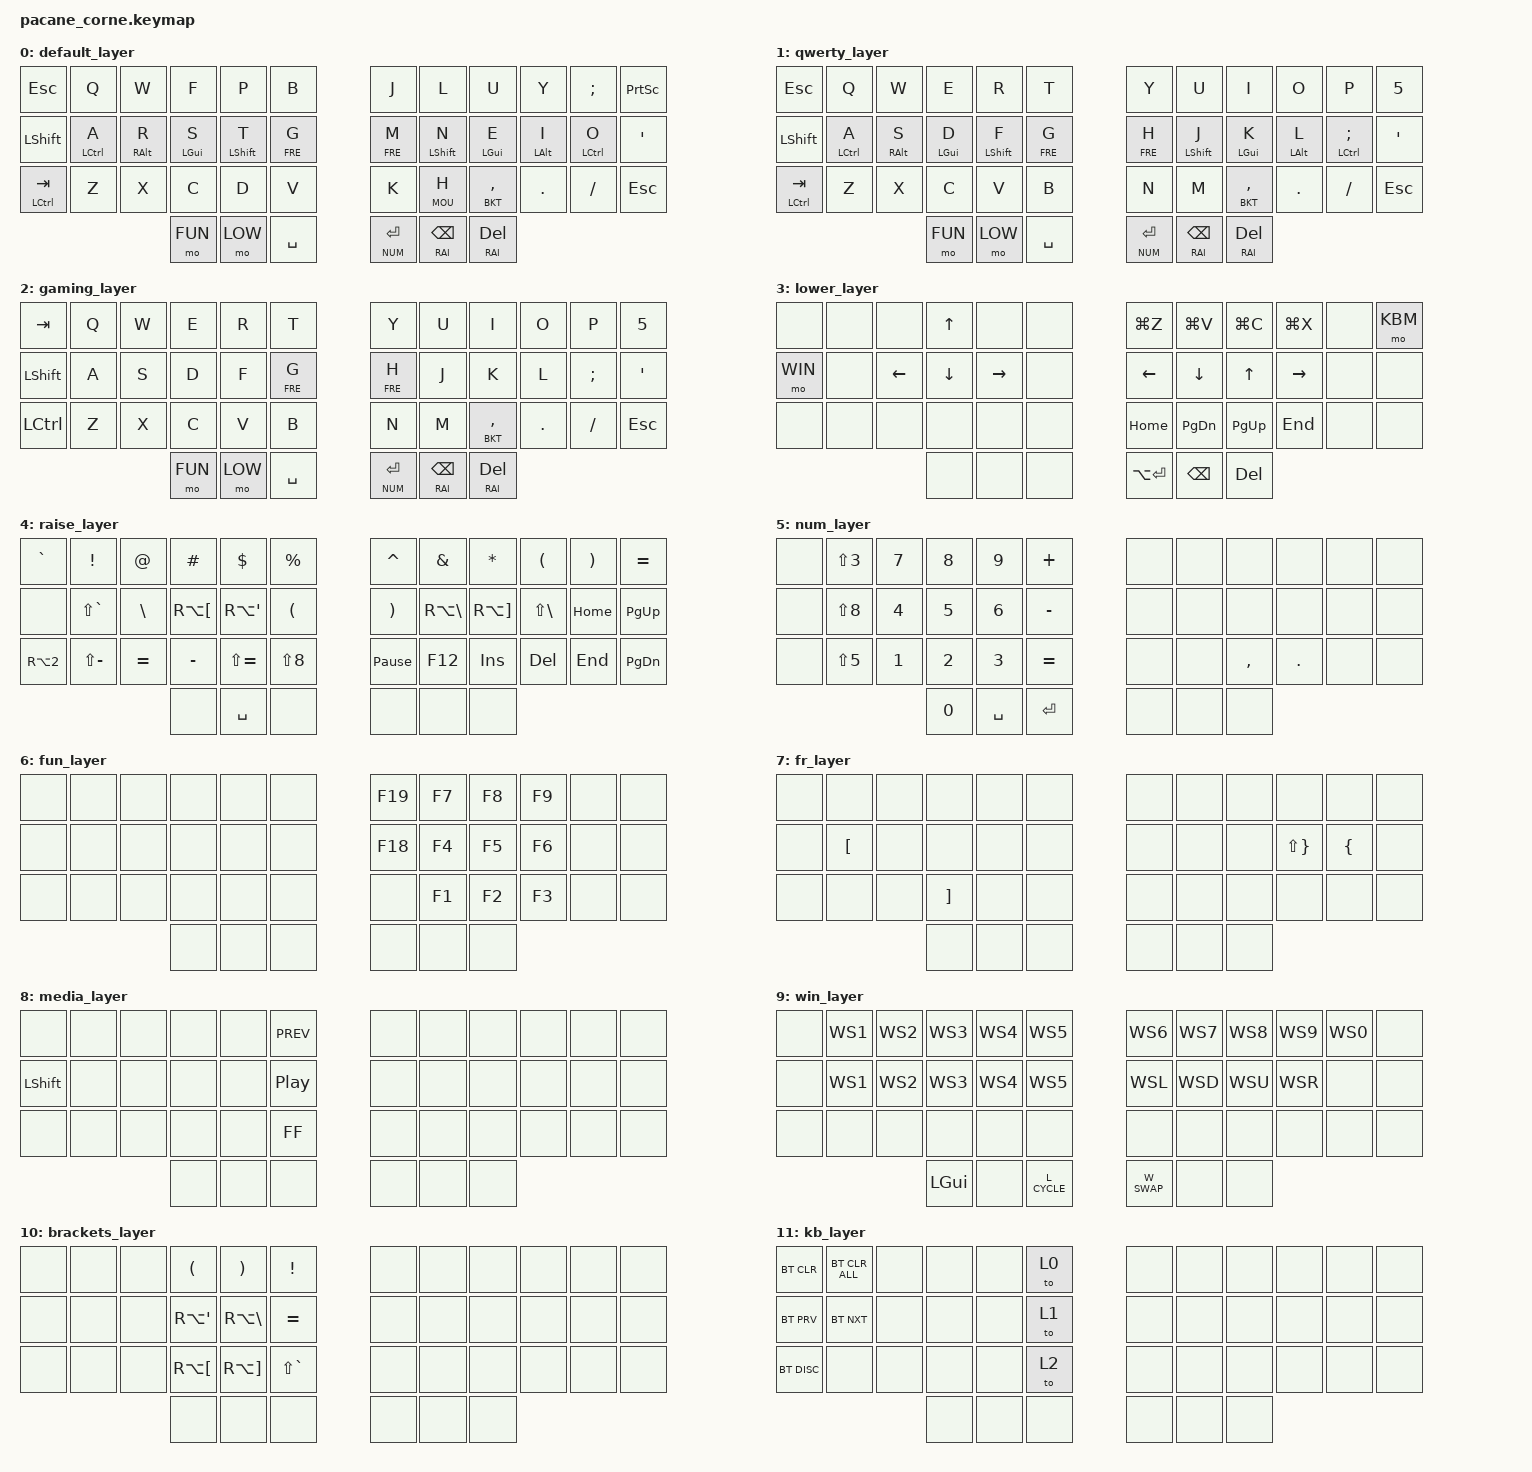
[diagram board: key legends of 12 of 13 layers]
#include <behaviors.dtsi>
#include <dt-bindings/zmk/keys.h>
#include <dt-bindings/zmk/bt.h>
#include "zmk-helpers/helper.h"

#define ZMK_POINTING_DEFAULT_MOVE_VAL 1500  // default: 600

#include <dt-bindings/zmk/mouse.h>
#include <dt-bindings/zmk/pointing.h>

#define L_SQ_BKT &kp RA(LBKT)
#define R_SQ_BKT &kp RA(RBKT)

#define L_CL_BKT &kp RA(SQT)
#define R_CL_BKT &kp RA(BSLH)

#define L_CHEV &kp BSLH
#define R_CHEV &kp LS(BSLH)

#define _PLUS &kp LS(EQUAL)
#define _PIPE &kp LS(GRAVE)
#define UNDSCR &kp LS(MINUS)
#define MULTPL &kp LS(N8)
#define _AT &kp RA(N2)
#define AMPRS &kp LS(N7)
#define TREMA &kp LS(RBRC)

#define WS1 LC(LS(LA(N1)))
#define WS2 LC(LS(LA(N2)))
#define WS3 LC(LS(LA(N3)))
#define WS4 LC(LS(LA(N4)))
#define WS5 LC(LS(LA(N5)))
#define WS6 LC(LS(LA(N6)))
#define WS7 LC(LS(LA(N7)))
#define WS8 LC(LS(LA(N8)))
#define WS9 LC(LS(LA(N9)))
#define WS0 LC(LS(LA(N0)))

#define WSL LC(LS(LA(H)))
#define WSD LC(LS(LA(J)))
#define WSU LC(LS(LA(K)))
#define WSR LC(LS(LA(L)))

#define T_FLOAT LC(LS(LA(T)))
#define W_SWAP  LC(LS(LA(RET)))
#define L_CYCLE LC(LS(LA(SPACE)))

// 0   1  2  3  4  5   6  7  8  9 10 11
// 12 13 14 15 16 17  18 19 20 21 22 23
// 24 25 26 27 28 29  30 31 32 33 34 35
//          36 37 38  39 40 41

#define KEYS_L 0 1 2 3 4 5 12 13 14 15 16 17 24 25 26 27 28 29
#define KEYS_R 6 7 8 9 10 11 18 19 20 21 22 23 30 31 32 33 34 35
#define THUMBS 36 37 38 39 40 41

/* left-hand HRMs */
ZMK_HOLD_TAP(hml,
    flavor = "balanced";
    tapping-term-ms = <280>;
    quick-tap-ms = <175>;                // repeat on tap-into-hold
    require-prior-idle-ms = <150>;
    bindings = <&kp>, <&kp>;
    hold-trigger-key-positions = <KEYS_R THUMBS>;
    hold-trigger-on-release;             // delay positional check until key-release
)

/* right-hand HRMs */
ZMK_HOLD_TAP(hmr,
    flavor = "balanced";
    tapping-term-ms = <280>;
    quick-tap-ms = <175>;                // repeat on tap-into-hold
    require-prior-idle-ms = <150>;
    bindings = <&kp>, <&kp>;
    hold-trigger-key-positions = <KEYS_L THUMBS>;
    hold-trigger-on-release;             // delay positional check until key-release
)


/ {
    macros {
        cced: cced {
            compatible = "zmk,behavior-macro";
            #binding-cells = <0>;
            bindings
                = <&macro_tap &kp RBKT>
                , <&macro_tap &kp C>
                ;
        };

        passwd: passwd {
            compatible = "zmk,behavior-macro";
            #binding-cells = <0>;
            bindings
                = <&macro_tap &kp M>
                , <&macro_tap &kp O>
                , <&macro_tap &kp T>
                , <&macro_tap &kp D>
                , <&macro_tap &kp E>
                , <&macro_tap &kp P>
                , <&macro_tap &kp A>
                , <&macro_tap &kp S>
                , <&macro_tap &kp S>
                , <&macro_tap &kp E>
                , <&macro_tap &kp N1>
                , <&macro_tap &kp N2>
                , <&macro_tap &kp N3>
                , <&macro_tap &kp N4>
                ;
        };
    };
};

#define COL 0
#define QWE 1
#define GAM 2
#define LOW 3
#define RAI 4
#define NUM 5
#define FUN 6
#define FRE 7
#define MED 8
#define WIN 9
#define BKT 10
#define KBM 11
#define MOU 12

/ {
    keymap {
	compatible = "zmk,keymap";


	default_layer {
	    bindings = <
    &kp ESC 	  &kp Q	       &kp W	   &kp F       &kp P        &kp B	&kp J     &kp L        &kp U         &kp Y       &kp SCLN     &kp PSCRN
    &kp LSHIFT	  &hml LCTRL A &hml RALT R &hml LGUI S &hml LSHFT T &lt FRE G	&lt FRE M &hmr LSHFT N &hmr LGUI E   &hmr LALT I &hmr LCTRL O &kp SQT
    &mt LCTRL TAB &kp Z	       &kp X	   &kp C       &kp D        &kp V	&kp K     &lt MOU H    &lt BKT COMMA &kp DOT     &kp FSLH     &kp ESC
		                     	       &mo FUN &mo LOW &kp SPACE        &lt NUM RET &lt RAI BSPC &lt RAI DEL
	    >;
	};
	
	qwerty_layer {
	    bindings = <
    &kp ESC	  &kp Q	       &kp W	   &kp E       &kp R        &kp T	&kp Y     &kp U        &kp I         &kp O       &kp P           &kp N5
    &kp LSHIFT	  &hml LCTRL A &hml RALT S &hml LGUI D &hml LSHFT F &lt FRE G	&lt FRE H &hmr LSHFT J &hmr LGUI K   &hmr LALT L &hmr LCTRL SCLN &kp SQT
    &mt LCTRL TAB &kp Z	       &kp X	   &kp C       &kp V        &kp B	&kp N     &kp M        &lt BKT COMMA &kp DOT     &kp FSLH        &kp ESC
    		                     	       &mo FUN &mo LOW &kp SPACE             &lt NUM RET &lt RAI BSPC &lt RAI DEL
	    >;
	};

	gaming_layer {
	    bindings = <
    &kp TAB	  &kp Q	       &kp W	   &kp E       &kp R        &kp T	&kp Y   &kp U        &kp I        &kp O       &kp P           &kp N5
    &kp LSHIFT	  &kp A        &kp S	   &kp D       &kp F	    &lt FRE G	&lt FRE H &kp J	     &kp K	  &kp L	      &kp SCLN	      &kp SQT
    &kp LCTRL 	  &kp Z	       &kp X	   &kp C       &kp V        &kp B	&kp N   &kp M        &lt BKT  COMMA  &kp DOT     &kp FSLH        &kp ESC
        		                     &mo FUN &mo LOW &kp SPACE             &lt NUM RET &lt RAI BSPC &lt RAI DEL
	    >;
	};

	lower_layer {
	    bindings = <
    &none &none &none	 &kp UP    &none     &none	&kp LG(Z) &kp LG(V) &kp LG(C) &kp LG(X) &none &mo KBM
    &mo WIN  &none &kp LEFT &kp DOWN  &kp RIGHT &none	&kp LEFT  &kp DOWN  &kp UP    &kp RIGHT &none &none
    &none &none &none    &none     &none     &none	&kp HOME  &kp PG_DN &kp PG_UP &kp END   &none &none
		  	 	   	     &none &none &none		&kp LA(RET) &kp BSPC &kp DEL
	    >;
	};

	raise_layer {
	    bindings = <
    &kp GRAVE &kp EXCL &kp AT    &kp HASH  &kp DLLR &kp PRCNT     &kp CARET       &kp AMPS &kp STAR &kp LPAR &kp RPAR &kp EQUAL
    &none     _PIPE    L_CHEV    L_SQ_BKT  L_CL_BKT &kp LPAR      &kp RPAR        R_CL_BKT R_SQ_BKT R_CHEV   &kp HOME &kp PG_UP
    _AT       UNDSCR   &kp EQUAL &kp MINUS _PLUS    MULTPL	  &kp PAUSE_BREAK &kp F12  &kp INS  &kp DEL  &kp END  &kp PG_DN
		       	   	     	     &none &kp SPACE &none			  &none      &none      &none 
	    >;
	};

	num_layer {
	    bindings = <
    &none &kp LS(N3) &kp N7  &kp N8 &kp N9 &kp PLUS	&none &none &none     &none   &none &none
    &none &kp LS(N8) &kp N4  &kp N5 &kp N6 &kp MINUS    &none &none &none     &none   &none &none
    &none &kp LS(N5) &kp N1  &kp N2 &kp N3 &kp EQUAL    &none &none &kp COMMA &kp DOT &none &none
		     	     	 &kp N0 &kp SPC &kp RET	   &none &none &none 
	    >;
	};

	fun_layer {
	    bindings = <
    &none &none  &none &none &none &none            &kp F19 &kp F7  &kp F8  &kp F9  &none &none
    &none &none  &none &none &none &none            &kp F18 &kp F4  &kp F5  &kp F6  &none &none
    &none &none  &none &none &none &none            &none   &kp F1  &kp F2  &kp F3  &none &none
	   	       &none &none &none	    &none &none  &none
	    >;
	};

	fr_layer {
	    bindings = <
    &none &none    &none &none    &none &none            &none &none &none &none &none    &none
    &none &kp LBKT &none &none    &none &none            &none &none &none TREMA &kp LBRC &none
    &none &none    &none &kp RBKT &none &none            &none &none &none &none &none    &none
	   	   	 &none    &none &none		     &none &none  &none
	    >;
	};

	media_layer {
	    bindings = <
    &none     &none &none &none &none &kp C_PREV       &none &none &none &none &none &none
    &kp LSHFT &none &none &none &none &kp C_PP         &none &none &none &none &none &none
    &none     &none &none &none &none &kp C_FF         &none &none &none &none &none &none
	      	     &none    &none &none		     &none &none  &none
	    >;
	};
	
	win_layer {
	    bindings = <
    &none &kp WS1 &kp WS2 &kp WS3  &kp WS4 &kp WS5          &kp WS6 &kp WS7 &kp WS8 &kp WS9 &kp WS0 &none
    &none &kp WS1 &kp WS2 &kp WS3  &kp WS4 &kp WS5          &kp WSL &kp WSD &kp WSU &kp WSR &none   &none
    &none &none   &none   &none    &none   &none            &none   &none   &none   &none   &none   &none
	  	  	   &kp LGUI &none &kp L_CYCLE               &kp W_SWAP &none &none
	    >;
	};

	brackets_layer {
	    bindings = <
    &none &none  &none &kp LPAR &kp RPAR &kp EXCL    &none &none &none &none &none &none
    &none &none  &none L_CL_BKT R_CL_BKT &kp EQUAL   &none &none &none &none &none &none
    &none &none  &none L_SQ_BKT R_SQ_BKT _PIPE       &none &none &none &none &none &none
	     	        &none &none &none		 &none &none &none 
	    >;
	};


	kb_layer {
	    bindings = <
    &bt BT_CLR  &bt BT_CLR_ALL &none &none &none  &to 0     &none &none &none &none &none      &none
    &bt BT_PRV  &bt BT_NXT     &none &none &none  &to 1     &none &none &none &none &none      &none
    &bt BT_DISC &none          &none &none &none  &to 2     &none &none &none &none &none      &none
	  		       	     &none &none &none	    &none &none &none
	    >;
	};

	mouse_layer {
	    bindings = <
    &none &none &none	       &mmv MOVE_UP   &none           &mkp MB2  &none &none &none &none &none      &none
    &none &none &mmv MOVE_LEFT &mmv MOVE_DOWN &mmv MOVE_RIGHT &mkp MB1  &none &none &none &none &none      &none
    &none &none &none          &none          &none           &none     &none &none &none &none &none      &none
	  		       	     &none &none &none	    &none &none &none
	    >;
	};

    };
};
